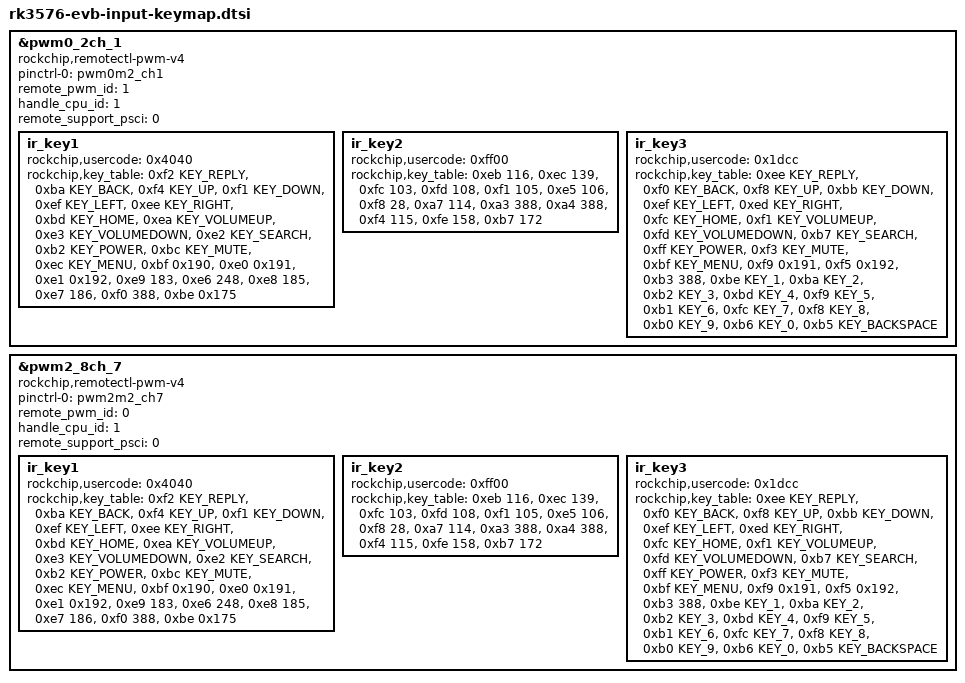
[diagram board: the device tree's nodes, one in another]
// SPDX-License-Identifier: (GPL-2.0+ OR MIT)
/*
 * Copyright (c) 2024 Rockchip Electronics Co., Ltd.
 *
 */

#include <dt-bindings/input/rk-ir.h>

&pwm0_2ch_1 {
	compatible = "rockchip,remotectl-pwm-v4";
	pinctrl-names = "default";
	pinctrl-0 = <&pwm0m2_ch1>;
	remote_pwm_id = <1>;
	handle_cpu_id = <1>;
	remote_support_psci = <0>;
	status = "okay";

	ir_key1 {
		rockchip,usercode = <0x4040>;
		rockchip,key_table =
			<0xf2	KEY_REPLY>,
			<0xba	KEY_BACK>,
			<0xf4	KEY_UP>,
			<0xf1	KEY_DOWN>,
			<0xef	KEY_LEFT>,
			<0xee	KEY_RIGHT>,
			<0xbd	KEY_HOME>,
			<0xea	KEY_VOLUMEUP>,
			<0xe3	KEY_VOLUMEDOWN>,
			<0xe2	KEY_SEARCH>,
			<0xb2	KEY_POWER>,
			<0xbc	KEY_MUTE>,
			<0xec	KEY_MENU>,
			<0xbf	0x190>,
			<0xe0	0x191>,
			<0xe1	0x192>,
			<0xe9	183>,
			<0xe6	248>,
			<0xe8	185>,
			<0xe7	186>,
			<0xf0	388>,
			<0xbe	0x175>;
	};

	ir_key2 {
		rockchip,usercode = <0xff00>;
		rockchip,key_table =
			<0xeb 116>,//KEY_POWER
			<0xec 139>,//KEY_MENU
			<0xfc 103>,//KEY_UP
			<0xfd 108>,//KEY_DOWN
			<0xf1 105>,//KEY_LEFT
			<0xe5 106>,//KEY_RIGHT
			<0xf8 28>, //KEY_Enter
			<0xa7 114>,//KEY_VOLUMEDOWN
			<0xa3 388>,
			<0xa4 388>,//KEY_CURSOR
			<0xf4 115>,//KEY_VOLUMEUP
			<0xfe 158>,//KEY_BACK
			<0xb7 172>;//KEY_HOMEPAGE
	};

	ir_key3 {
		rockchip,usercode = <0x1dcc>;
		rockchip,key_table =
			<0xee	KEY_REPLY>,
			<0xf0	KEY_BACK>,
			<0xf8	KEY_UP>,
			<0xbb	KEY_DOWN>,
			<0xef	KEY_LEFT>,
			<0xed	KEY_RIGHT>,
			<0xfc	KEY_HOME>,
			<0xf1	KEY_VOLUMEUP>,
			<0xfd	KEY_VOLUMEDOWN>,
			<0xb7	KEY_SEARCH>,
			<0xff	KEY_POWER>,
			<0xf3	KEY_MUTE>,
			<0xbf	KEY_MENU>,
			<0xf9	0x191>,
			<0xf5	0x192>,
			<0xb3	388>,
			<0xbe	KEY_1>,
			<0xba	KEY_2>,
			<0xb2	KEY_3>,
			<0xbd	KEY_4>,
			<0xf9	KEY_5>,
			<0xb1	KEY_6>,
			<0xfc	KEY_7>,
			<0xf8	KEY_8>,
			<0xb0	KEY_9>,
			<0xb6	KEY_0>,
			<0xb5	KEY_BACKSPACE>;
	};
};

&pwm2_8ch_7 {
	compatible = "rockchip,remotectl-pwm-v4";
	pinctrl-names = "default";
	pinctrl-0 = <&pwm2m2_ch7>;
	remote_pwm_id = <0>;
	handle_cpu_id = <1>;
	remote_support_psci = <0>;
	status = "okay";

	ir_key1 {
		rockchip,usercode = <0x4040>;
		rockchip,key_table =
			<0xf2	KEY_REPLY>,
			<0xba	KEY_BACK>,
			<0xf4	KEY_UP>,
			<0xf1	KEY_DOWN>,
			<0xef	KEY_LEFT>,
			<0xee	KEY_RIGHT>,
			<0xbd	KEY_HOME>,
			<0xea	KEY_VOLUMEUP>,
			<0xe3	KEY_VOLUMEDOWN>,
			<0xe2	KEY_SEARCH>,
			<0xb2	KEY_POWER>,
			<0xbc	KEY_MUTE>,
			<0xec	KEY_MENU>,
			<0xbf	0x190>,
			<0xe0	0x191>,
			<0xe1	0x192>,
			<0xe9	183>,
			<0xe6	248>,
			<0xe8	185>,
			<0xe7	186>,
			<0xf0	388>,
			<0xbe	0x175>;
	};

	ir_key2 {
		rockchip,usercode = <0xff00>;
		rockchip,key_table =
			<0xeb 116>,//KEY_POWER
			<0xec 139>,//KEY_MENU
			<0xfc 103>,//KEY_UP
			<0xfd 108>,//KEY_DOWN
			<0xf1 105>,//KEY_LEFT
			<0xe5 106>,//KEY_RIGHT
			<0xf8 28>, //KEY_Enter
			<0xa7 114>,//KEY_VOLUMEDOWN
			<0xa3 388>,
			<0xa4 388>,//KEY_CURSOR
			<0xf4 115>,//KEY_VOLUMEUP
			<0xfe 158>,//KEY_BACK
			<0xb7 172>;//KEY_HOMEPAGE
	};

	ir_key3 {
		rockchip,usercode = <0x1dcc>;
		rockchip,key_table =
			<0xee	KEY_REPLY>,
			<0xf0	KEY_BACK>,
			<0xf8	KEY_UP>,
			<0xbb	KEY_DOWN>,
			<0xef	KEY_LEFT>,
			<0xed	KEY_RIGHT>,
			<0xfc	KEY_HOME>,
			<0xf1	KEY_VOLUMEUP>,
			<0xfd	KEY_VOLUMEDOWN>,
			<0xb7	KEY_SEARCH>,
			<0xff	KEY_POWER>,
			<0xf3	KEY_MUTE>,
			<0xbf	KEY_MENU>,
			<0xf9	0x191>,
			<0xf5	0x192>,
			<0xb3	388>,
			<0xbe	KEY_1>,
			<0xba	KEY_2>,
			<0xb2	KEY_3>,
			<0xbd	KEY_4>,
			<0xf9	KEY_5>,
			<0xb1	KEY_6>,
			<0xfc	KEY_7>,
			<0xf8	KEY_8>,
			<0xb0	KEY_9>,
			<0xb6	KEY_0>,
			<0xb5	KEY_BACKSPACE>;
	};
};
